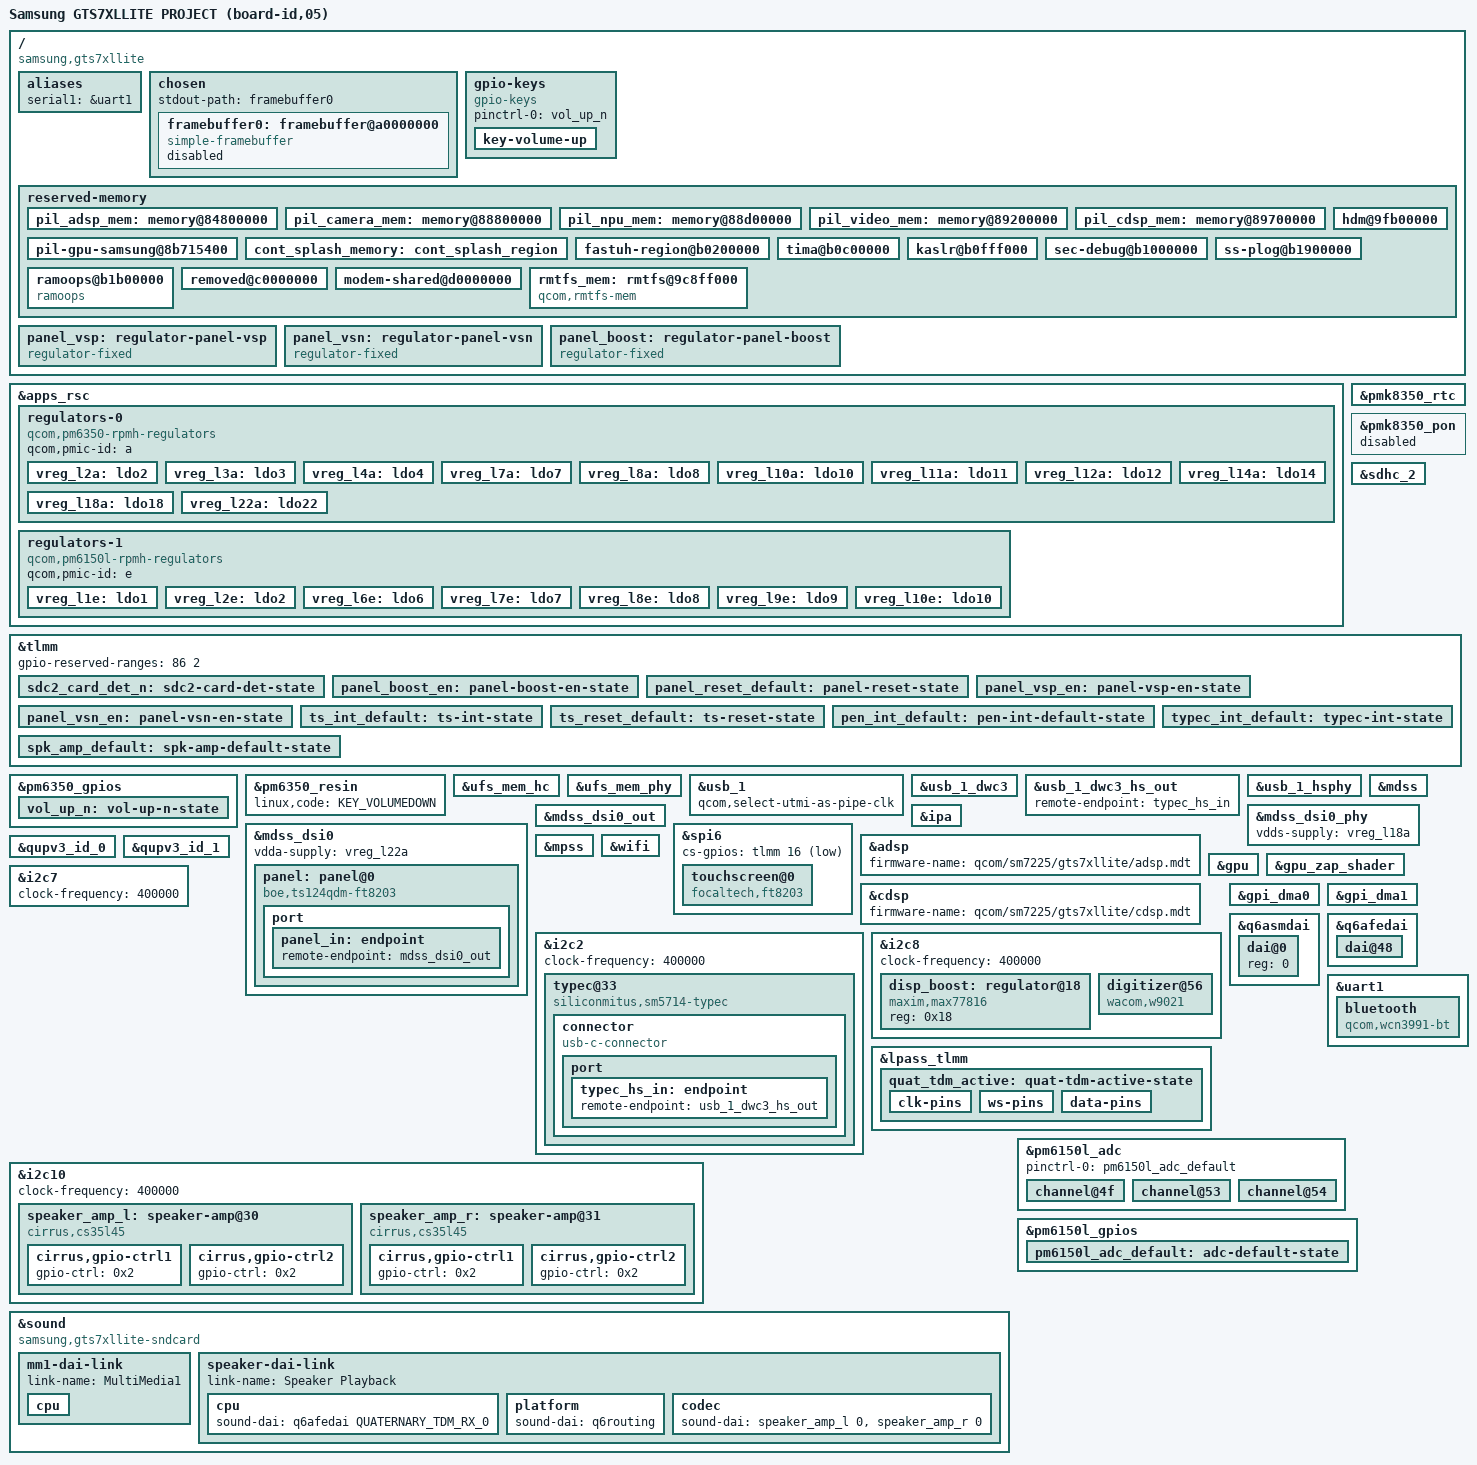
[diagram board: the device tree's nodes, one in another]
// SPDX-License-Identifier: BSD-3-Clause
/*
 * Samsung Galaxy Tab S7 FE LTE (SM-T735, gts7xllite)
 *
 * FIRST-BOOT DRAFT: CPU, memory, regulators, UFS, USB (peripheral),
 * buttons, and the bootloader splash as a simple framebuffer.
 * Everything else is intentionally left out.
 *
 * Values taken from the downstream Samsung DTB (board-id 8/5).
 */

/* PMK8350 (in reality a PMK8003) is configured to use SID6 instead of 0 */
#define PMK8350_SID 6

/dts-v1/;

#include <dt-bindings/firmware/qcom,scm.h>
#include <dt-bindings/gpio/gpio.h>
#include <dt-bindings/input/input.h>
#include <dt-bindings/pinctrl/qcom,pmic-gpio.h>
#include <dt-bindings/regulator/qcom,rpmh-regulator.h>
#include <dt-bindings/sound/cs35l45.h>
#include <dt-bindings/sound/qcom,q6asm.h>
#include <dt-bindings/usb/pd.h>

#include "sm7225.dtsi"
#include "pm6150l.dtsi"
#include "pm6350.dtsi"
#include "pmk8350.dtsi"
#include "gts7xllite-sm5714.dtsi"

/delete-node/ &cont_splash_memory;

/ {
	model = "Samsung GTS7XLLITE PROJECT (board-id,05)";
	compatible = "samsung,gts7xllite", "qcom,lagoon-mtp", "qcom,lagoon", "qcom,mtp", "qcom,sm7225";
	chassis-type = "tablet";

	qcom,msm-id = <434 0x10000>, <459 0x10000>;
	qcom,board-id = <8 5>;
	dtbo-version = <0>;

	aliases {
		serial1 = &uart1;
	};

	chosen {
		#address-cells = <2>;
		#size-cells = <2>;
		ranges;

		stdout-path = "framebuffer0";

		/* Bootloader splash (cont_splash_region), panel 1600x2560 */
		framebuffer0: framebuffer@a0000000 {
			status = "disabled";
			compatible = "simple-framebuffer";
			reg = <0 0xa0000000 0 (1600 * 2560 * 4)>;
			width = <1600>;
			height = <2560>;
			stride = <(1600 * 4)>;
			format = "a8r8g8b8";
		};
	};

	gpio-keys {
		compatible = "gpio-keys";
		pinctrl-0 = <&vol_up_n>;
		pinctrl-names = "default";

		key-volume-up {
			label = "Volume Up";
			gpios = <&pm6350_gpios 2 GPIO_ACTIVE_LOW>;
			linux,code = <KEY_VOLUMEUP>;
			debounce-interval = <15>;
		};
	};

	reserved-memory {
		/* Fairphone ramoops from sm6350.dtsi: drop it so ours is the only one */
		/delete-node/ ramoops@ffc00000;
		/delete-node/ memory@c0000000;
		/delete-node/ fastuh_heap;

		/* Samsung relocates the DSP carveouts (stock overlay fragments 118-122) */
		/delete-node/ memory@86000000;	/* pil_camera_mem */
		/delete-node/ memory@86500000;	/* pil_npu_mem */
		/delete-node/ memory@86a00000;	/* pil_video_mem */
		/delete-node/ memory@86f00000;	/* pil_cdsp_mem */
		/delete-node/ memory@88d00000;	/* pil_adsp_mem */

		pil_adsp_mem: memory@84800000 {
			reg = <0 0x84800000 0 0x4000000>;
			no-map;
		};

		pil_camera_mem: memory@88800000 {
			reg = <0 0x88800000 0 0x500000>;
			no-map;
		};

		pil_npu_mem: memory@88d00000 {
			reg = <0 0x88d00000 0 0x500000>;
			no-map;
		};

		pil_video_mem: memory@89200000 {
			reg = <0 0x89200000 0 0x500000>;
			no-map;
		};

		pil_cdsp_mem: memory@89700000 {
			reg = <0 0x89700000 0 0x1e00000>;
			no-map;
		};

		/* Samsung GPU firmware region */
		pil-gpu-samsung@8b715400 {
			reg = <0 0x8b715400 0 0x2000>;
			no-map;
		};

		/* Splash buffer: must stay untouched for simplefb */
			cont_splash_memory: cont_splash_region {
			reg = <0 0xa0000000 0 0x2300000>;
			label = "cont_splash_region";
			no-map;
		};

		/* Samsung-specific carveouts (secure world / uH / debug) */
		hdm@9fb00000 {
			reg = <0 0x9fb00000 0 0x1000>;
			no-map;
		};

		fastuh-region@b0200000 {
			reg = <0 0xb0200000 0 0x200000>;
			no-map;
		};

		tima@b0c00000 {
			reg = <0 0xb0c00000 0 0x100000>;
			no-map;
		};

		kaslr@b0fff000 {
			reg = <0 0xb0fff000 0 0x1000>;
			no-map;
		};

		sec-debug@b1000000 {
			reg = <0 0xb1000000 0 0x900000>;
			no-map;
		};

		ss-plog@b1900000 {
			reg = <0 0xb1900000 0 0x200000>;
			no-map;
		};

		/* Same region as Samsung's ramoops: readable from OrangeFox after a crash */
		ramoops@b1b00000 {
			compatible = "ramoops";
			reg = <0 0xb1b00000 0 0x100000>;
			record-size = <0x40000>;
			console-size = <0x40000>;
			ftrace-size = <0x40000>;
			pmsg-size = <0x40000>;
		};

		/* Samsung bootloader adding fastuh-heap by itself */
		/* fastuh-heap@b2000000 {
			reg = <0 0xb2000000 0 0xe00000>;
			no-map;
		}; */

		removed@c0000000 {
			reg = <0 0xc0000000 0 0x5e00000>;
			no-map;
		};

		modem-shared@d0000000 {
			reg = <0 0xd0000000 0 0x6000000>;
			no-map;
		};

		/* rmtfs: modem EFS buffer (downstream qcom,rmtfs_sharedmem, 0x280000 + guard pages) */
		rmtfs_mem: rmtfs@9c8ff000 {
			compatible = "qcom,rmtfs-mem";
			reg = <0 0x9c8ff000 0 0x282000>;
			no-map;

			qcom,client-id = <1>;
			qcom,vmid = <QCOM_SCM_VMID_MSS_MSA>;
			qcom,use-guard-pages;
		};
	};

	/* Samsung panel (FT8203 regulator) */
	panel_vsp: regulator-panel-vsp {
		compatible = "regulator-fixed";
		regulator-name = "panel_buck_en";
		gpio = <&tlmm 88 GPIO_ACTIVE_HIGH>;
		enable-active-high;
		pinctrl-0 = <&panel_vsp_en>;
		pinctrl-names = "default";
	};

	panel_vsn: regulator-panel-vsn {
		compatible = "regulator-fixed";
		regulator-name = "panel_buck_en2";
		gpio = <&tlmm 89 GPIO_ACTIVE_HIGH>;
		enable-active-high;
		pinctrl-0 = <&panel_vsn_en>;
		pinctrl-names = "default";
	};

	panel_boost: regulator-panel-boost {
		compatible = "regulator-fixed";
		regulator-name = "panel_boost_en";
		gpio = <&tlmm 72 GPIO_ACTIVE_HIGH>;
		enable-active-high;
		pinctrl-0 = <&panel_boost_en>;
		pinctrl-names = "default";
	};
};

&apps_rsc {
	regulators-0 {
		compatible = "qcom,pm6350-rpmh-regulators";
		qcom,pmic-id = "a";

		vreg_l2a: ldo2 {
			regulator-name = "vreg_l2a";
			regulator-min-microvolt = <1503000>;
			regulator-max-microvolt = <1980000>;
			regulator-initial-mode = <RPMH_REGULATOR_MODE_HPM>;
		};

		vreg_l3a: ldo3 {
			regulator-name = "vreg_l3a";
			regulator-min-microvolt = <2700000>;
			regulator-max-microvolt = <3300000>;
			regulator-initial-mode = <RPMH_REGULATOR_MODE_HPM>;
		};

		/* WCN3990 CX/MX (downstream pm6350_l4) */
		vreg_l4a: ldo4 {
			regulator-name = "vreg_l4a";
			regulator-min-microvolt = <352000>;
			regulator-max-microvolt = <800000>;
			regulator-initial-mode = <RPMH_REGULATOR_MODE_HPM>;
		};

		/* WCN3990 XO 1.8 V (downstream pm6350_l7, 1.62-1.98 V) */
		vreg_l7a: ldo7 {
			regulator-name = "vreg_l7a";
			regulator-min-microvolt = <1800000>;
			regulator-max-microvolt = <1800000>;
			regulator-initial-mode = <RPMH_REGULATOR_MODE_HPM>;
		};

		/* WACOM E PEN */
		vreg_l8a: ldo8 {
			regulator-name = "vreg_l8a";		/* wacom_avdd, 3.3 V */
			regulator-min-microvolt = <3296000>;
			regulator-max-microvolt = <3304000>;
			regulator-initial-mode = <RPMH_REGULATOR_MODE_HPM>;
		};

		vreg_l10a: ldo10 {
			regulator-name = "vreg_l10a";
			regulator-min-microvolt = <3296000>;
			regulator-max-microvolt = <3304000>;
			regulator-initial-mode = <RPMH_REGULATOR_MODE_HPM>;
			regulator-always-on;
		};

		vreg_l11a: ldo11 {
			regulator-name = "vreg_l11a";
			regulator-min-microvolt = <1800000>;
			regulator-max-microvolt = <1904000>;
			regulator-initial-mode = <RPMH_REGULATOR_MODE_HPM>;
		};

		vreg_l12a: ldo12 {
			regulator-name = "vreg_l12a";
			regulator-min-microvolt = <1800000>;
			regulator-max-microvolt = <1800000>;
			regulator-initial-mode = <RPMH_REGULATOR_MODE_HPM>;
		};

		/* panel_ldo_en downstream: keep on so the splash stays visible */
		vreg_l14a: ldo14 {
			regulator-name = "vreg_l14a";
			regulator-min-microvolt = <1896000>;
			regulator-max-microvolt = <1904000>;
			regulator-initial-mode = <RPMH_REGULATOR_MODE_HPM>;
			regulator-always-on;
			regulator-boot-on;
		};

		vreg_l18a: ldo18 {
			regulator-name = "vreg_l18a";
			regulator-min-microvolt = <880000>;
			regulator-max-microvolt = <1049000>;
			regulator-initial-mode = <RPMH_REGULATOR_MODE_HPM>;
		};

		vreg_l22a: ldo22 {
			regulator-name = "vreg_l22a";
			regulator-min-microvolt = <1200000>;
			regulator-max-microvolt = <1305000>;
			regulator-initial-mode = <RPMH_REGULATOR_MODE_HPM>;
		};
		
	};

	/* Downstream calls it "pm6150a", resources are ldoeX/smpeX = pm6150l at id "e" */
	regulators-1 {
		compatible = "qcom,pm6150l-rpmh-regulators";
		qcom,pmic-id = "e";

		vreg_l1e: ldo1 {
			regulator-name = "vreg_l1e";
			regulator-min-microvolt = <1800000>;
			regulator-max-microvolt = <1800000>;
			regulator-initial-mode = <RPMH_REGULATOR_MODE_HPM>;
			regulator-always-on;
		};

		/* WCN3990 RF 1.3 V (downstream pm6150a_l2, config 1.224-1.304 V) */
		vreg_l2e: ldo2 {
			regulator-name = "vreg_l2e";
			regulator-min-microvolt = <1224000>;
			regulator-max-microvolt = <1304000>;
			regulator-initial-mode = <RPMH_REGULATOR_MODE_HPM>;
		};

		/* microSD I/O (downstream pm6150a_l6) */
		vreg_l6e: ldo6 {
			regulator-name = "vreg_l6e";
			regulator-min-microvolt = <1800000>;
			regulator-max-microvolt = <2952000>;
			regulator-initial-mode = <RPMH_REGULATOR_MODE_HPM>;
		};

		/* UFS VCC */
		vreg_l7e: ldo7 {
			regulator-name = "vreg_l7e";
			regulator-min-microvolt = <2952000>;
			regulator-max-microvolt = <2960000>;
			regulator-initial-mode = <RPMH_REGULATOR_MODE_HPM>;
		};

		vreg_l8e: ldo8 {
			regulator-name = "vreg_l8e";
			regulator-min-microvolt = <1800000>;
			regulator-max-microvolt = <1800000>;
			regulator-initial-mode = <RPMH_REGULATOR_MODE_HPM>;
			regulator-always-on;
		};

		/* microSD card power (downstream pm6150a_l9) */
		vreg_l9e: ldo9 {
			regulator-name = "vreg_l9e";
			regulator-min-microvolt = <2960000>;
			regulator-max-microvolt = <2960000>;
			regulator-initial-mode = <RPMH_REGULATOR_MODE_HPM>;
		};

		/* WCN3990 RF chain 0, 3.3 V (downstream pm6150a_l10, config 3.0-3.3 V) */
		vreg_l10e: ldo10 {
			regulator-name = "vreg_l10e";
			regulator-min-microvolt = <3000000>;
			regulator-max-microvolt = <3304000>;
			regulator-initial-mode = <RPMH_REGULATOR_MODE_HPM>;
		};

		
	};
};

&pmk8350_rtc {
	status = "okay";
};

/* pm6350's PON already handles power and volume-down; avoid a second PON driver */
&pmk8350_pon {
	status = "disabled";
};

&sdhc_2 {
	vmmc-supply = <&vreg_l9e>;
	vqmmc-supply = <&vreg_l6e>;
	cd-gpios = <&tlmm 94 GPIO_ACTIVE_LOW>;

	pinctrl-0 = <&sdc2_on_state>, <&sdc2_card_det_n>;
	pinctrl-1 = <&sdc2_off_state>, <&sdc2_card_det_n>;
	pinctrl-names = "default", "sleep";

	status = "okay";
};

&tlmm {
	gpio-reserved-ranges = <86 2>;

	/* microSD card detect: Samsung's cd_on (gpio94, 2 mA, pull-up) */
	sdc2_card_det_n: sdc2-card-det-state {
		pins = "gpio94";
		function = "gpio";
		drive-strength = <2>;
		bias-pull-up;
	};

	/* Samsung panel (FT8203) */
	panel_boost_en: panel-boost-en-state {
		pins = "gpio72";
		function = "gpio";
		drive-strength = <2>;
		bias-disable;
	};

	panel_reset_default: panel-reset-state {
		pins = "gpio73";
		function = "gpio";
		drive-strength = <2>;
		bias-disable;
	};

	panel_vsp_en: panel-vsp-en-state {
		pins = "gpio88";
		function = "gpio";
		drive-strength = <2>;
		bias-disable;
	};

	panel_vsn_en: panel-vsn-en-state {
		pins = "gpio89";
		function = "gpio";
		drive-strength = <2>;
		bias-disable;
	};

	/* Touch (FT8203 TDDI, SPI on QUP SE6) */
	ts_int_default: ts-int-state {
		pins = "gpio22";
		function = "gpio";
		drive-strength = <2>;
		bias-pull-up;
	};

	ts_reset_default: ts-reset-state {
		pins = "gpio18";
		function = "gpio";
		drive-strength = <2>;
		bias-disable;
	};

	/* WACOM PEN W9021 */
	pen_int_default: pen-int-default-state { 
	pins = "gpio85";
	function = "gpio";
	bias-disable;
	input-enable;
	};
};

&pm6350_gpios {
	vol_up_n: vol-up-n-state {
		pins = "gpio2";
		function = "normal";
		power-source = <0>;
		bias-pull-up;
		input-enable;
	};
};

&pm6350_resin {
	linux,code = <KEY_VOLUMEDOWN>;
	status = "okay";
};

&ufs_mem_hc {
	/* TODO: confirm GPIO against sm7225-fairphone-fp4.dts */
	reset-gpios = <&tlmm 156 GPIO_ACTIVE_LOW>;

	vcc-supply = <&vreg_l7e>;
	vcc-max-microamp = <800000>;
	vccq2-supply = <&vreg_l12a>;
	vccq2-max-microamp = <800000>;

	status = "okay";
};

&ufs_mem_phy {
	vdda-phy-supply = <&vreg_l18a>;
	vdda-pll-supply = <&vreg_l22a>;

	status = "okay";
};

&usb_1 {
	/* USB2-only: take the pipe clock from the HS PHY (no USB3 PHY in use) */
	qcom,select-utmi-as-pipe-clk;
	status = "okay";
};

/* Dual-role, USB2-only for now. Role set via /sys/class/usb_role until
 * an SM5714 Type-C driver exists; boots as peripheral so NCM keeps working. */
&usb_1_dwc3 {
	dr_mode = "otg";
	usb-role-switch;
	role-switch-default-mode = "peripheral";
	maximum-speed = "high-speed";
	phys = <&usb_1_hsphy>;
	phy-names = "usb2-phy";
};

&usb_1_dwc3_hs_out {
	remote-endpoint = <&typec_hs_in>;
};


&usb_1_hsphy {
	vdd-supply = <&vreg_l18a>;
	vdda-pll-supply = <&vreg_l2a>;
	vdda-phy-dpdm-supply = <&vreg_l3a>;

	status = "okay";
};

/* ------------------------------------------------------------------ */
/* FT8203 SCREEN */
&mdss {
	status = "okay";
};

&mdss_dsi0 {
	vdda-supply = <&vreg_l22a>;
	status = "okay";

	panel: panel@0 {
		compatible = "boe,ts124qdm-ft8203";
		reg = <0>;

		vddi-supply = <&vreg_l14a>;
		vsp-supply = <&panel_vsp>;
		vsn-supply = <&panel_vsn>;
		boost-supply = <&panel_boost>;
		reset-gpios = <&tlmm 73 GPIO_ACTIVE_LOW>;

		pinctrl-0 = <&panel_reset_default>;
		pinctrl-names = "default";

		samsung,boost = <&disp_boost>;

		port {
			panel_in: endpoint {
				remote-endpoint = <&mdss_dsi0_out>;
			};
		};
	};
};

&mdss_dsi0_out {
	data-lanes = <0 1 2 3>;
	remote-endpoint = <&panel_in>;
};

&mdss_dsi0_phy {
	vdds-supply = <&vreg_l18a>;
	status = "okay";
};

/* touch screen use SPI instead of I2C*/
&spi6 {		/* QUP SE6, use the label from sm6350.dtsi */
	status = "okay";
	cs-gpios = <&tlmm 16 GPIO_ACTIVE_LOW>;

	touchscreen@0 {
		compatible = "focaltech,ft8203";
		reg = <0>;
		spi-max-frequency = <6000000>;
		interrupts-extended = <&tlmm 22 IRQ_TYPE_EDGE_FALLING>;
		reset-gpios = <&tlmm 18 GPIO_ACTIVE_LOW>;
		touchscreen-size-x = <1600>;
		touchscreen-size-y = <2560>;
		firmware-name = "tsp_focaltech/ft8203_gts7xllite.bin";

		pinctrl-names = "default";
		pinctrl-0 = <&ts_int_default>, <&ts_reset_default>;

		panel = <&panel>;
	};
};

/* ------------------------------------------------------------------ */

&ipa {
	qcom,gsi-loader = "self";
	memory-region = <&pil_ipa_fw_mem>;
	firmware-name = "qcom/sm7225/gts7xllite/lagoon_ipa_fws.mdt";
	status = "okay";
};

/* ------------------------------------------------------------------ */
&adsp {
	firmware-name = "qcom/sm7225/gts7xllite/adsp.mdt";
	status = "okay";
};

&cdsp {
	firmware-name = "qcom/sm7225/gts7xllite/cdsp.mdt";
	status = "okay";
};

&mpss {
	firmware-name = "qcom/sm7225/gts7xllite/modem.mdt";
	status = "okay";
};

&wifi {
	interrupts = <GIC_SPI 414 IRQ_TYPE_EDGE_RISING>,
		     <GIC_SPI 415 IRQ_TYPE_EDGE_RISING>,
		     <GIC_SPI 416 IRQ_TYPE_EDGE_RISING>,
		     <GIC_SPI 417 IRQ_TYPE_EDGE_RISING>,
		     <GIC_SPI 418 IRQ_TYPE_EDGE_RISING>,
		     <GIC_SPI 419 IRQ_TYPE_EDGE_RISING>,
		     <GIC_SPI 420 IRQ_TYPE_EDGE_RISING>,
		     <GIC_SPI 421 IRQ_TYPE_EDGE_RISING>,
		     <GIC_SPI 422 IRQ_TYPE_EDGE_RISING>,
		     <GIC_SPI 423 IRQ_TYPE_EDGE_RISING>,
		     <GIC_SPI 424 IRQ_TYPE_EDGE_RISING>,
		     <GIC_SPI 425 IRQ_TYPE_EDGE_RISING>;

	vdd-0.8-cx-mx-supply = <&vreg_l4a>;
	vdd-1.8-xo-supply = <&vreg_l7a>;
	vdd-1.3-rfa-supply = <&vreg_l2e>;
	vdd-3.3-ch0-supply = <&vreg_l10e>;
	qcom,calibration-variant = "samsung_gts7xllite";
	local-mac-address = [00 00 00 00 00 00];
	status = "okay";
};
/* ------------------------------------------------------------------ */
/* sm5714 fuel guage */
&qupv3_id_0 {
	status = "okay";
};

&qupv3_id_1 {
	status = "okay";
};

/* ------------------------------------------------------------------ */
/* GPU and zap shader */
&gpu {
	status = "okay";
};

&gpu_zap_shader {
	firmware-name = "qcom/sm7225/gts7xllite/a615_zap.mdt";
};

/* ------------------------------------------------------------------ */

&i2c2 {
	clock-frequency = <400000>;
	status = "okay";

	typec@33 {
		compatible = "siliconmitus,sm5714-typec";
		reg = <0x33>;
		interrupts-extended = <&tlmm 7 IRQ_TYPE_LEVEL_LOW>;
		pinctrl-0 = <&typec_int_default>;
		pinctrl-names = "default";

		vbus-supply = <&usb_otg_vbus>;
		siliconmitus,muic = <&sm5714>;

		connector {
			compatible = "usb-c-connector";
			label = "USB-C";
			data-role = "dual";
			power-role = "dual";
			try-power-role = "sink";
			self-powered;

			/* as source (OTG): 5 V 0.9 A */
			source-pdos = <PDO_FIXED(5000, 900, PDO_FIXED_DUAL_ROLE |
						 PDO_FIXED_DATA_SWAP |
						 PDO_FIXED_USB_COMM)>;
			sink-pdos = <PDO_FIXED(5000, 3000, PDO_FIXED_DUAL_ROLE |
					       PDO_FIXED_DATA_SWAP |
					       PDO_FIXED_USB_COMM)
				     PDO_FIXED(9000, 2000, 0)>;
			op-sink-microwatt = <15000000>;

			port {
				typec_hs_in: endpoint {
					remote-endpoint = <&usb_1_dwc3_hs_out>;
				};
			};
		};
	};
};

&tlmm {
	typec_int_default: typec-int-state {
		pins = "gpio7";
		function = "gpio";
		drive-strength = <2>;
		bias-pull-up;
	};
};


&i2c7 {
	clock-frequency = <400000>;
	status = "okay";

	/* SM5714 MFD @ 49 (IRQ TLMM 84) */
	/* SM5440 direct charger @ 63 */
};

&i2c8 {
	clock-frequency = <400000>;
	status = "okay";

	/* MAX77816 buck-boost: backlight 5 V input, programmed by the panel driver */
	disp_boost: regulator@18 {
		compatible = "maxim,max77816";
		reg = <0x18>;
	};

	digitizer@56 {
		compatible = "wacom,w9021";
		reg = <0x56>;

		interrupts-extended = <&tlmm 85 IRQ_TYPE_LEVEL_LOW>;
		pinctrl-0 = <&pen_int_default>;
		pinctrl-names = "default";

		vdd-supply = <&vreg_l8a>;

		/*
		 * FWE (flash-mode) is TLMM 86: still in gpio-reserved-ranges and
		 * held low by the board, so it is left out (optional property).
		 */

		/* raw chip X runs bottom->top along the 266 mm side, raw Y left->right */
		touchscreen-inverted-x;
		touchscreen-swapped-x-y;
		touchscreen-x-mm = <266>;
		touchscreen-y-mm = <166>;
	};

	/* WACOM EPEN */
	/* THIS NEED gpi_dma1 enabled */
};

&gpi_dma0 {
	status = "okay";
};

&gpi_dma1 {
	status = "okay";
};

/* ------------------------------------------------------------------ */
/* speaker */
&i2c10 {
	clock-frequency = <400000>;
	status = "okay";

	speaker_amp_l: speaker-amp@30 {
		compatible = "cirrus,cs35l45";
		reg = <0x30>;
		interrupts-extended = <&tlmm 54 IRQ_TYPE_LEVEL_LOW>;
		reset-gpios = <&tlmm 55 GPIO_ACTIVE_HIGH>;
		pinctrl-0 = <&spk_amp_default>;
		pinctrl-names = "default";
		cirrus,asp-sdout-hiz-ctrl = <(CS35L45_ASP_TX_HIZ_UNUSED | CS35L45_ASP_TX_HIZ_DISABLED)>;
		sound-name-prefix = "SpkrLeft";
		#sound-dai-cells = <1>;

		cirrus,gpio-ctrl1 { gpio-ctrl = <0x2>; };
		cirrus,gpio-ctrl2 { gpio-ctrl = <0x2>; };
	};

	speaker_amp_r: speaker-amp@31 {
		compatible = "cirrus,cs35l45";
		reg = <0x31>;
		interrupts-extended = <&tlmm 54 IRQ_TYPE_LEVEL_LOW>;
		reset-gpios = <&tlmm 55 GPIO_ACTIVE_HIGH>;
		cirrus,asp-sdout-hiz-ctrl = <(CS35L45_ASP_TX_HIZ_UNUSED | CS35L45_ASP_TX_HIZ_DISABLED)>;
		sound-name-prefix = "SpkrRight";
		#sound-dai-cells = <1>;

		cirrus,gpio-ctrl1 { gpio-ctrl = <0x2>; };
		cirrus,gpio-ctrl2 { gpio-ctrl = <0x2>; };
	};
};

&tlmm {
	spk_amp_default: spk-amp-default-state {
		pins = "gpio54", "gpio55";
		function = "gpio";
		drive-strength = <2>;
		bias-disable;
	};
};

&q6asmdai {
	dai@0 {
		reg = <0>;
	};
};

&q6afedai {
	dai@48 {
		reg = <QUATERNARY_TDM_RX_0>;
		qcom,tdm-sync-mode = <0>;
		qcom,tdm-sync-src = <1>;
		qcom,tdm-data-out = <0>;
		qcom,tdm-invert-sync = <0>;
		qcom,tdm-data-delay = <1>;
		qcom,tdm-data-align = <0>;
		
		qcom,tdm-lane-mask = <0x1>;	/* sd0 (Samsung: lane-mask [00 01]) */
	};
};

&lpass_tlmm {
	quat_tdm_active: quat-tdm-active-state {
		clk-pins {
			pins = "gpio0";
			function = "qua_mi2s_sclk";
			drive-strength = <8>;
			bias-disable;
			output-high;
		};
		ws-pins {
			pins = "gpio1";
			function = "qua_mi2s_ws";
			drive-strength = <8>;
			bias-disable;
			output-high;
		};
		data-pins {
			pins = "gpio2", "gpio3";
			function = "qua_mi2s_data";
			drive-strength = <8>;
			bias-disable;
		};
	};
};

&sound {
	compatible = "samsung,gts7xllite-sndcard";
	model = "Samsung Galaxy Tab S7 FE";
	pinctrl-0 = <&quat_tdm_active>;
	pinctrl-names = "default";

	mm1-dai-link {
		link-name = "MultiMedia1";
		cpu {
			sound-dai = <&q6asmdai MSM_FRONTEND_DAI_MULTIMEDIA1>;
		};
	};

	speaker-dai-link {
		link-name = "Speaker Playback";
		cpu {
			sound-dai = <&q6afedai QUATERNARY_TDM_RX_0>;
		};
		platform {
			sound-dai = <&q6routing>;
		};
		codec {
			sound-dai = <&speaker_amp_l 0>, <&speaker_amp_r 0>;
		};
	};
};

/* ------------------------------------------------------------------ */
/* bluetooth */

&qupv3_id_0 {
	status = "okay";
};

&uart1 {
	status = "okay";

	bluetooth {
		compatible = "qcom,wcn3991-bt";

		vddio-supply = <&vreg_l11a>;
		vddxo-supply = <&vreg_l7a>;
		vddrf-supply = <&vreg_l2e>;
		vddch0-supply = <&vreg_l10e>;
		swctrl-gpios = <&tlmm 69 GPIO_ACTIVE_HIGH>;

		max-speed = <3200000>;

		local-bd-address = [00 00 00 00 00 00];
	};
};

&pm6150l_adc {
	pinctrl-0 = <&pm6150l_adc_default>;
	pinctrl-names = "default";

	channel@4f {
		reg = <ADC5_AMUX_THM3_100K_PU>;
		label = "blkt_therm";
		qcom,hw-settle-time = <200>;
		qcom,pre-scaling = <1 1>;
		qcom,ratiometric;
	};

	channel@53 {
		reg = <ADC5_GPIO2_100K_PU>;
		label = "batt_therm";
		qcom,hw-settle-time = <200>;
		qcom,pre-scaling = <1 1>;
		qcom,ratiometric;
	};

	channel@54 {
		reg = <ADC5_GPIO3_100K_PU>;
		label = "chg_therm";
		qcom,hw-settle-time = <200>;
		qcom,pre-scaling = <1 1>;
		qcom,ratiometric;
	};
};

&pm6150l_gpios {
	/* thermistor inputs: PMIC GPIO pins as analog (high-Z), as on FP4 */
	pm6150l_adc_default: adc-default-state {
		pins = "gpio6", "gpio7";
		function = PMIC_GPIO_FUNC_NORMAL;
		bias-high-impedance;
	};
};
